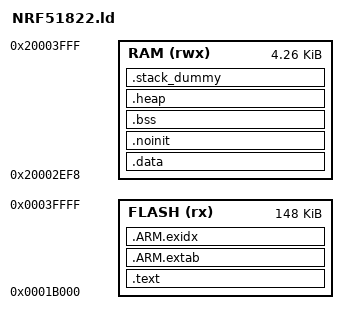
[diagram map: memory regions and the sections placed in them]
/* Linker script to configure memory regions. */

#if !defined(MBED_BOOT_STACK_SIZE)
    #define MBED_BOOT_STACK_SIZE 0x800
#endif

MEMORY
{
  FLASH (rx) : ORIGIN = 0x0001B000, LENGTH = 0x25000
  RAM (rwx) :  ORIGIN = 0x20002ef8, LENGTH = 0x1108
}

OUTPUT_FORMAT ("elf32-littlearm", "elf32-bigarm", "elf32-littlearm")

/* Linker script to place sections and symbol values. Should be used together
 * with other linker script that defines memory regions FLASH and RAM.
 * It references following symbols, which must be defined in code:
 *   Reset_Handler : Entry of reset handler
 *
 * It defines following symbols, which code can use without definition:
 *   __exidx_start
 *   __exidx_end
 *   __etext
 *   __data_start__
 *   __preinit_array_start
 *   __preinit_array_end
 *   __init_array_start
 *   __init_array_end
 *   __fini_array_start
 *   __fini_array_end
 *   __data_end__
 *   __bss_start__
 *   __bss_end__
 *   __end__
 *   end
 *   __HeapLimit
 *   __StackLimit
 *   __StackTop
 *   __stack
 */
ENTRY(Reset_Handler)

SECTIONS
{
	.text :
	{
		KEEP(*(.Vectors))
		*(.text*)

		KEEP(*(.init))
		KEEP(*(.fini))

		/* .ctors */
		*crtbegin.o(.ctors)
		*crtbegin?.o(.ctors)
		*(EXCLUDE_FILE(*crtend?.o *crtend.o) .ctors)
		*(SORT(.ctors.*))
		*(.ctors)

		/* .dtors */
 		*crtbegin.o(.dtors)
 		*crtbegin?.o(.dtors)
 		*(EXCLUDE_FILE(*crtend?.o *crtend.o) .dtors)
 		*(SORT(.dtors.*))
 		*(.dtors)

		*(.rodata*)

		KEEP(*(.eh_frame*))
	} > FLASH


	.ARM.extab :
	{
		*(.ARM.extab* .gnu.linkonce.armextab.*)
	} > FLASH

	__exidx_start = .;
	.ARM.exidx :
	{
		*(.ARM.exidx* .gnu.linkonce.armexidx.*)
	} > FLASH
	__exidx_end = .;

	__etext = .;

	.data : AT (__etext)
	{
		__data_start__ = .;
		*(vtable)
		*(.data*)

		. = ALIGN(8);
		/* preinit data */
		PROVIDE_HIDDEN (__preinit_array_start = .);
		KEEP(*(.preinit_array))
		PROVIDE_HIDDEN (__preinit_array_end = .);

		. = ALIGN(8);
		/* init data */
		PROVIDE_HIDDEN (__init_array_start = .);
		KEEP(*(SORT(.init_array.*)))
		KEEP(*(.init_array))
		PROVIDE_HIDDEN (__init_array_end = .);


		. = ALIGN(8);
		/* finit data */
		PROVIDE_HIDDEN (__fini_array_start = .);
		KEEP(*(SORT(.fini_array.*)))
		KEEP(*(.fini_array))
		PROVIDE_HIDDEN (__fini_array_end = .);
        
		. = ALIGN(8);
		PROVIDE(__start_fs_data = .);
		KEEP(*(.fs_data))
		PROVIDE(__stop_fs_data = .);

		*(.jcr)
		. = ALIGN(8);
		/* All data end */
		__data_end__ = .;

	} > RAM

    .noinit :
    {
      PROVIDE(__start_noinit = .);
      KEEP(*(.noinit))
      PROVIDE(__stop_noinit = .);
    } > RAM
    
	.bss :
	{
		. = ALIGN(8);
		__bss_start__ = .;
		*(.bss*)
		*(COMMON)
		. = ALIGN(8);
		__bss_end__ = .;
	} > RAM

	.heap (NOLOAD):
	{
		__end__ = .;
		end = __end__;
		__HeapBase = .;
		*(.heap*)
		. = ORIGIN(RAM) + LENGTH(RAM) - MBED_BOOT_STACK_SIZE;
		__HeapLimit = .;
	} > RAM

	/* .stack_dummy section doesn't contains any symbols. It is only
	 * used for linker to calculate size of stack sections, and assign
	 * values to stack symbols later */
	.stack_dummy (NOLOAD):
	{
		*(.stack*)
	} > RAM

	/* Set stack top to end of RAM, and stack limit move down by
	 * size of stack_dummy section */
	__StackTop = ORIGIN(RAM) + LENGTH(RAM);
	__StackLimit = __StackTop - MBED_BOOT_STACK_SIZE;
	PROVIDE(__stack = __StackTop);

	/* Check if data + heap + stack exceeds RAM limit */
	ASSERT(__StackLimit >= __HeapLimit, "region RAM overflowed with stack")
}
